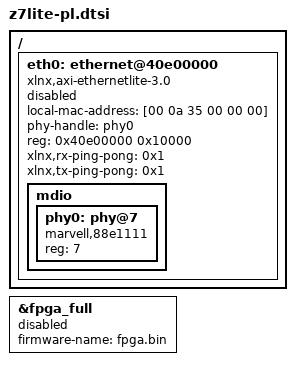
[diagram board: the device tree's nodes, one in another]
/ {
	eth0: ethernet@40e00000 {
		compatible = "xlnx,axi-ethernetlite-3.0", "xlnx,xps-ethernetlite-1.00.a";
		status = "disabled";
		device_type = "network";
		local-mac-address = [00 0a 35 00 00 00];
		phy-handle = <&phy0>;
		reg = <0x40e00000 0x10000>;
	 	xlnx,rx-ping-pong = <0x1>;
		xlnx,tx-ping-pong = <0x1>;
		mdio {
			#address-cells = <1>;
			#size-cells = <0>;
			phy0: phy@7 {
				compatible = "marvell,88e1111";
				device_type = "ethernet-phy";
				reg = <7>;
			};
		};
	};
};

&fpga_full {
	firmware-name = "fpga.bin";
	status = "disabled";
};
